AUTOSAR XML (schema 4-3-0)
standard types defined: boolean, uint16, uint8, boolean_CompuMethod, boolean_DataConstr, uint16_DataConstr, uint8_DataConstr, sint16
package /ComponentTypes/HkmcComponent/HkmcFcaAdap/DataTypes
  18 x impl type, all with sw-calibration-access=READ-ONLY, type-emitter=RTE:
    FcaAdap_CollisionThreatLevel_T: category=VALUE, base-type=BaseTypes/uint8, compu {0=Cx0_CollisionTL_Unknown, 1=Cx1_CollisionTL_ThreatLow, 2=Cx2_CollisionTL_ThreatMedium, 3=Cx3_CollisionTL_ThreatHigh}
    FcaAdap_DclReqVal_T: category=VALUE, base-type=BaseTypes/uint8
    FcaAdap_DecelerationRequest_T: category=VALUE, base-type=BaseTypes/uint8
    FcaAdap_FullActvReq_T: category=VALUE, base-type=BaseTypes/uint8
    FcaAdap_LongitudinalVelocity_T: category=VALUE, base-type=sint16
    FcaAdap_ObjectType_T: category=VALUE, base-type=BaseTypes/uint8, compu {0=Cx0_ObT_Unknown, 1=Cx1_ObT_Car, 2=Cx2_ObT_Motorcycle, 3=Cx3_ObT_Truck, 4=Cx4_ObT_Pedestrian, 5=Cx5_ObT_Bicycle, 6=Cx6_ObT_GeneralObject}
    FcaAdap_OnOffEquipSta_T: category=VALUE, base-type=BaseTypes/uint8, compu {0=Cx0_OnOffES_Default, 1=Cx1_OnOffES_Off, 2=Cx2_OnOffES_Warning, 3=Cx3_OnOffES_Assist, 4=Cx4_OnOffES_Reserved, 5=Cx5_OnOffES_Reserved, 6=Cx6_OnOffES_Reserved, 7=Cx7_OnOffES_Invalid}
    FcaAdap_PrefillActvReq_T: category=VALUE, base-type=BaseTypes/uint8, compu {0=Cx0_PrefillAR_No_Pre_fill, 1=Cx1_PrefillAR_Pre_fill_act, 2=Cx2_PrefillAR_Reserved, 3=Cx3_PrefillAR_Error_Indicator}
    FcaAdap_RelVel_T: category=VALUE, base-type=BaseTypes/uint16
    FcaAdap_SnstvtyModRetVal_T: category=VALUE, base-type=BaseTypes/uint8, compu {0=Cx0_LongV_Default, 1=Cx1_LongV_Off, 2=Cx2_LongV_Warning, 3=Cx3_LongV_Assist, 4=Cx4_LongV_Reserved, 5=Cx5_LongV_Reserved, 6=Cx6_LongV_Reserved, 7=Cx7_LongV_Invalid}
    FcaAdap_StbltActvReq_T: category=VALUE, base-type=BaseTypes/uint8, compu {0=Cx0_StbltAR_Release_no_alert, 1=Cx1_StbltAR_Precrash_full_retraction, 2=Cx2_StbltAR_Haptic_Warning, 3=Cx3_StbltAR_Reserved, 4=Cx4_StbltAR_Reserved, 5=Cx5_StbltAR_Reserved, 6=Cx6_StbltAR_Reserved, 7=Cx7_StbltAR_Reserved}
    FcaAdap_SysFlrSta_T: category=VALUE, base-type=BaseTypes/uint8, compu {0=Cx0_SysFlrS_Normal, 1=Cx1_SysFlrS_Temp_Unavailable_by_Camera, 2=Cx2_SysFlrS_Temp_Unavailable_by_Radar, 3=Cx3_SysFlrS_Service_Required, 4=Cx4_SysFlrS_Temp_Unavailable_by_Camera, 5=Cx5_SysFlrS_Reserved, 6=Cx6_SysFlrS_Reserved, 7=Cx7_SysFlrS_Reserved}
    FcaAdap_TimetoCllsn_T: category=VALUE, base-type=BaseTypes/uint8
    FcaAdap_VehStpReq_T: category=VALUE, base-type=BaseTypes/uint8, compu {0=Cx0_VehSR_No_Request, 1=Cx1_VehSR_Stop_control_is_required, 2=Cx2_VehSR_Reserved, 3=Cx3_VehSR_Error_Indicator}
    FcaAdap_WarningRequest_T: category=VALUE, base-type=BaseTypes/boolean
    FcaAdap_WrngLvlSta_T: category=VALUE, base-type=BaseTypes/uint8, compu {0=Cx0_WrngLS_No_warning, 1=Cx1_WrngLS_Warning_Level_1, 2=Cx2_WrngLS_Warning_Level_2, 3=Cx3_WrngLS_Warning_Level_3}
    FcaAdap_WrngSndSta_T: category=VALUE, base-type=BaseTypes/uint8, compu {0=Cx0_WrngSS_No_warning, 1=Cx1_WrngSS_Warning_Level_1, 2=Cx2_WrngSS_Warning_Level_2, 3=Cx3_WrngSS_Warning_Level_3}
    HFA_OUTPUTS_T: category=STRUCTURE
      18 x element, all with category=TYPE_REFERENCE:
        FcaAdap_WrngLvlSta: implementation-data-type=FcaAdap_WrngLvlSta_T
        FcaAdap_WrngSndSta: implementation-data-type=FcaAdap_WrngSndSta_T
        FcaAdap_PrefillActvReq: implementation-data-type=FcaAdap_PrefillActvReq_T
        FcaAdap_DclReqVal: implementation-data-type=FcaAdap_DclReqVal_T
        FcaAdap_FullActvReq: implementation-data-type=FcaAdap_FullActvReq_T
        FcaAdap_StbltActvReq: implementation-data-type=FcaAdap_StbltActvReq_T
        FcaAdap_VehStpReq: implementation-data-type=FcaAdap_VehStpReq_T
        FcaAdap_OnOffEquipSta: implementation-data-type=FcaAdap_OnOffEquipSta_T
        FcaAdap_SysFlrSta: implementation-data-type=FcaAdap_SysFlrSta_T
        FcaAdap_RelVel: implementation-data-type=FcaAdap_RelVel_T
        FcaAdap_TimetoCllsn: implementation-data-type=FcaAdap_TimetoCllsn_T
        FcaAdap_SnstvtyModRetVal: implementation-data-type=FcaAdap_SnstvtyModRetVal_T
        FcaAdap_LongitudinalVelocity: implementation-data-type=FcaAdap_LongitudinalVelocity_T
        FcaAdap_ObjectType: implementation-data-type=FcaAdap_ObjectType_T
        FcaAdap_WarningRequest: implementation-data-type=FcaAdap_WarningRequest_T
        FcaAdap_CollisionThreatLevel: implementation-data-type=FcaAdap_CollisionThreatLevel_T
        FcaAdap_DecelerationRequest: implementation-data-type=FcaAdap_DecelerationRequest_T
        FcaAdap_StandStillRequest: implementation-data-type=boolean
package /ComponentTypes/HkmcComponent/HkmcFcaAdap/PortInterfaces
  sender receiver interface IF_HFA_OUTPUTS: invalidation-policy{data-element=DE_HFA_OUTPUTS, handle-invalid=DONT-INVALIDATE}
    data DE_HFA_OUTPUTS: type=HFA_OUTPUTS_T
package /ComponentTypes/HkmcComponent/HkmcVehicleOutputAdap
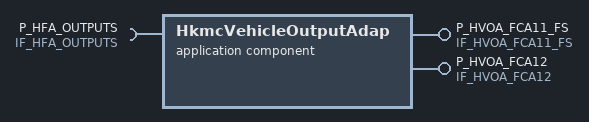
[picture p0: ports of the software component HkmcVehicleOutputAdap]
  application sw component type HkmcVehicleOutputAdap
    provide port P_HVOA_FCA11_FS: nonqueued-sender-com-spec=data-element=DE_HVOA_FCA11_FS, provided-interface=IF_HVOA_FCA11_FS
    provide port P_HVOA_FCA12: nonqueued-sender-com-spec=data-element=DE_HVOA_FCA12, provided-interface=IF_HVOA_FCA12
    require port P_HFA_OUTPUTS: nonqueued-receiver-com-spec{data-element=DE_HFA_OUTPUTS, filter=data-filter-type=ALWAYS, init-value=fields=[FcaAdap_WrngLvlSta:0, FcaAdap_WrngSndSta:0, FcaAdap_PrefillActvReq:0, FcaAdap_DclReqVal:0, FcaAdap_FullActvReq:0, FcaAdap_StbltActvReq:0, FcaAdap_VehStpReq:0, FcaAdap_OnOffEquipSta:0, FcaAdap_SysFlrSta:0, FcaAdap_RelVel:0, FcaAdap_TimetoCllsn:0, FcaAdap_SnstvtyModRetVal:0, FcaAdap_LongitudinalVelocity:0, FcaAdap_ObjectType:0, FcaAdap_WarningRequest:0, FcaAdap_CollisionThreatLevel:0, FcaAdap_DecelerationRequest:0, FcaAdap_StandStillRequest:0]}, required-interface=IF_HFA_OUTPUTS
    behavior HkmcVehicleOutputAdap_InternalBehavior
  swc implementation HkmcVehicleOutputAdap_Implementation: behavior=HkmcVehicleOutputAdap_InternalBehavior
    code-descriptors:
      code Default: artifact-descriptors=autosar-engineering-object={short-label=Default, category=SWSRC}
package /ComponentTypes/HkmcComponent/HkmcVehicleOutputAdap/DataTypes
  impl type HVOA_FCA11_FS_T: category=STRUCTURE, sw-calibration-access=READ-ONLY, type-emitter=RTE
    11 x element, all with category=TYPE_REFERENCE:
      CF_VSM_Warn: compu {0=Cx0_Warn_No_warning, 1=Cx1_Warn_Warning_Level_1, 2=Cx2_Warn_Warning_Level_2, 3=Cx3_Warn_Warning_Level_3}, implementation-data-type=uint8
      FCA_WrngSndSta: compu {0=Cx0_WrngSS_No_warning, 1=Cx1_WrngSS_Warning_Level_1, 2=Cx2_WrngSS_Warning_Level_2, 3=Cx3_WrngSS_Warning_Level_3}, implementation-data-type=uint8
      CF_VSM_Prefill: compu {0=Cx0_Prefill_No_Prefill, 1=Cx1_Prefill_Prefill}, implementation-data-type=boolean
      CR_VSM_DecCmd: implementation-data-type=uint8
      FCA_CmdAct: compu {0=Cx0_CmdA_No_Request, 1=Cx1_CmdA_Request_valid}, implementation-data-type=boolean
      CF_VSM_BeltCmd: compu {0=Cx0_BeltC_Release_no_alert, 1=Cx1_BeltC_Precrash_full_retraction, 2=Cx2_BeltC_Haptic_Warning}, implementation-data-type=boolean
      FCA_StopReq: compu {0=Cx0_StopR_No_Request, 1=Cx1_StopR_Stop_control_is_required}, implementation-data-type=boolean
      FCA_Status: compu {0=Cx0_Status_Not_Applied, 1=Cx1_Status_System_Off, 2=Cx2_Status_System_On, 3=Cx3_Status_Invalid}, implementation-data-type=boolean
      FCA_Failinfo: compu {0=Cx0_FailI_Normal, 1=Cx1_FailI_Temp_Unavailable_by_Camera, 2=Cx2_FailI_Temp_Unavailable_by_Radar, 3=Cx3_FailI_Service_Required, 4=Cx4_FailI_Temp_Unavailable_by_Camera_Only, 5=Cx5_FailI_Reserved, 6=Cx6_FailI_Reserved, 7=Cx7_FailI_Reserved}, implementation-data-type=uint8
      FCA_RelativeVelocity: implementation-data-type=uint16
      FCA_TimetoCollision: implementation-data-type=uint8
  impl type HVOA_FCA12_T: category=STRUCTURE, sw-calibration-access=READ-ONLY, type-emitter=RTE
    element FCA_DrvSetState: compu {0=Cx0_DrvSS_Default, 1=Cx1_DrvSS_Late, 2=Cx2_DrvSS_Normal, 3=Cx3_DrvSS_Early, 4=Cx4_DrvSS_Reserved, 5=Cx5_DrvSS_Reserved, 6=Cx6_DrvSS_Reserved, 7=Cx7_DrvSS_Invalid}, implementation-data-type=uint8
    element FCA_USM: compu {0=Cx0_USM_Default, 1=Cx1_USM_Off, 2=Cx2_USM_Warning, 3=Cx3_USM_Assist, 4=Cx4_USM_Reserved, 5=Cx5_USM_Reserved, 6=Cx6_USM_Reserved, 7=Cx7_USM_Invalid}, implementation-data-type=uint8
package /ComponentTypes/HkmcComponent/HkmcVehicleOutputAdap/PortInterfaces
  sender receiver interface IF_HVOA_FCA11_FS: invalidation-policy{data-element=DE_HVOA_FCA11_FS, handle-invalid=DONT-INVALIDATE}
    data DE_HVOA_FCA11_FS: type=HVOA_FCA11_FS_T
  sender receiver interface IF_HVOA_FCA12: invalidation-policy{data-element=DE_HVOA_FCA12, handle-invalid=DONT-INVALIDATE}
    data DE_HVOA_FCA12: type=HVOA_FCA12_T
